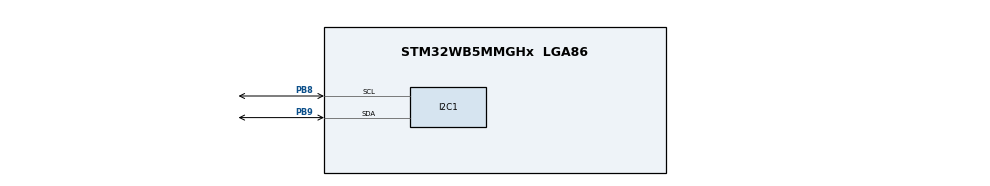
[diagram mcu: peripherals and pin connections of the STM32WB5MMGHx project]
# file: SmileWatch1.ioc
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I2C1.Timing=0x00100D14
Mcu.Family=STM32WB
Mcu.Name=STM32WB5MMGHx
Mcu.Package=LGA86
NVIC.PriorityGroup=NVIC_PRIORITYGROUP_4
PB8.Mode=I2C
PB8.Signal=I2C1_SCL
PB9.Mode=I2C
PB9.Signal=I2C1_SDA
ProjectManager.HeapSize=0x200
ProjectManager.StackSize=0x400
ProjectManager.TargetToolchain=STM32CubeIDE
RCC.APB3Freq_Value=16000000
RCC.HSE_VALUE=32000000
RCC.HSI48_VALUE=48000000
RCC.HSI_VALUE=16000000
RCC.VCOOutputFreq_Value=32000000
VP_MEMORYMAP_VS_MEMORYMAP.Mode=CurAppReg
board=custom

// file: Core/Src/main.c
/* USER CODE BEGIN Header */
/**
  ******************************************************************************
  * @file           : main.c
  * @brief          : Main program body — SmileWatch V2 (STM32WB55)
  ******************************************************************************
  * @attention
  *
  * Copyright (c) 2026 STMicroelectronics.
  * All rights reserved.
  *
  * This software is licensed under terms that can be found in the LICENSE file
  * in the root directory of this software component.
  * If no LICENSE file comes with this software, it is provided AS-IS.
  *
  ******************************************************************************
  */
/* USER CODE END Header */
#include "main.h"

/* USER CODE BEGIN Includes */
#include "smilewatch_ui.h"
/* USER CODE END Includes */

I2C_HandleTypeDef hi2c1;

void SystemClock_Config(void);
void PeriphCommonClock_Config(void);
static void MX_GPIO_Init(void);
static void MX_I2C1_Init(void);

int main(void)
{

  /* MCU Configuration--------------------------------------------------------*/

  /* Reset of all peripherals, Initializes the Flash interface and the Systick. */
  HAL_Init();

  /* Configure the system clock */
  SystemClock_Config();

  /* Configure the peripherals common clocks */
  PeriphCommonClock_Config();

  /* Initialize all configured peripherals */
  MX_GPIO_Init();
  MX_I2C1_Init();
  /* USER CODE BEGIN 2 */
  SmileWatch_Init(&hi2c1);
  /* USER CODE END 2 */

  /* Infinite loop */
  /* USER CODE BEGIN WHILE */
  while (1)
  {
    SmileWatch_LoopTask(HAL_GetTick());
    /* USER CODE END WHILE */

  }
}

void SystemClock_Config(void)
{
  RCC_OscInitTypeDef RCC_OscInitStruct = {0};
  RCC_ClkInitTypeDef RCC_ClkInitStruct = {0};

  /** Configure the main internal regulator output voltage
  */
  __HAL_PWR_VOLTAGESCALING_CONFIG(PWR_REGULATOR_VOLTAGE_SCALE1);

  /** Initializes the RCC Oscillators according to the specified parameters
  * in the RCC_OscInitTypeDef structure.
  */
  RCC_OscInitStruct.OscillatorType = RCC_OSCILLATORTYPE_HSI|RCC_OSCILLATORTYPE_MSI;
  RCC_OscInitStruct.HSIState = RCC_HSI_ON;
  RCC_OscInitStruct.MSIState = RCC_MSI_ON;
  RCC_OscInitStruct.HSICalibrationValue = RCC_HSICALIBRATION_DEFAULT;
  RCC_OscInitStruct.MSICalibrationValue = RCC_MSICALIBRATION_DEFAULT;
  RCC_OscInitStruct.MSIClockRange = RCC_MSIRANGE_6;
  RCC_OscInitStruct.PLL.PLLState = RCC_PLL_NONE;
  if (HAL_RCC_OscConfig(&RCC_OscInitStruct) != HAL_OK)
  {
    Error_Handler();
  }

  /** Configure the SYSCLKSource, HCLK, PCLK1 and PCLK2 clocks dividers
  */
  RCC_ClkInitStruct.ClockType = RCC_CLOCKTYPE_HCLK4|RCC_CLOCKTYPE_HCLK2
                              |RCC_CLOCKTYPE_HCLK|RCC_CLOCKTYPE_SYSCLK
                              |RCC_CLOCKTYPE_PCLK1|RCC_CLOCKTYPE_PCLK2;
  RCC_ClkInitStruct.SYSCLKSource = RCC_SYSCLKSOURCE_MSI;
  RCC_ClkInitStruct.AHBCLKDivider = RCC_SYSCLK_DIV1;
  RCC_ClkInitStruct.APB1CLKDivider = RCC_HCLK_DIV1;
  RCC_ClkInitStruct.APB2CLKDivider = RCC_HCLK_DIV1;
  RCC_ClkInitStruct.AHBCLK2Divider = RCC_SYSCLK_DIV1;
  RCC_ClkInitStruct.AHBCLK4Divider = RCC_SYSCLK_DIV1;

  if (HAL_RCC_ClockConfig(&RCC_ClkInitStruct, FLASH_LATENCY_0) != HAL_OK)
  {
    Error_Handler();
  }
}

void PeriphCommonClock_Config(void)
{
  RCC_PeriphCLKInitTypeDef PeriphClkInitStruct = {0};

  /** Initializes the peripherals clock
  */
  PeriphClkInitStruct.PeriphClockSelection = RCC_PERIPHCLK_SMPS;
  PeriphClkInitStruct.SmpsClockSelection = RCC_SMPSCLKSOURCE_HSI;
  PeriphClkInitStruct.SmpsDivSelection = RCC_SMPSCLKDIV_RANGE1;

  if (HAL_RCCEx_PeriphCLKConfig(&PeriphClkInitStruct) != HAL_OK)
  {
    Error_Handler();
  }
}

static void MX_I2C1_Init(void)
{

  hi2c1.Instance = I2C1;
  hi2c1.Init.Timing = 0x00100D14;
  hi2c1.Init.OwnAddress1 = 0;
  hi2c1.Init.AddressingMode = I2C_ADDRESSINGMODE_7BIT;
  hi2c1.Init.DualAddressMode = I2C_DUALADDRESS_DISABLE;
  hi2c1.Init.OwnAddress2 = 0;
  hi2c1.Init.OwnAddress2Masks = I2C_OA2_NOMASK;
  hi2c1.Init.GeneralCallMode = I2C_GENERALCALL_DISABLE;
  hi2c1.Init.NoStretchMode = I2C_NOSTRETCH_DISABLE;
  if (HAL_I2C_Init(&hi2c1) != HAL_OK)
  {
    Error_Handler();
  }

  /** Configure Analogue filter
  */
  if (HAL_I2CEx_ConfigAnalogFilter(&hi2c1, I2C_ANALOGFILTER_ENABLE) != HAL_OK)
  {
    Error_Handler();
  }

  /** Configure Digital filter
  */
  if (HAL_I2CEx_ConfigDigitalFilter(&hi2c1, 0) != HAL_OK)
  {
    Error_Handler();
  }

}

static void MX_GPIO_Init(void)
{

  /* GPIO Ports Clock Enable */
  __HAL_RCC_GPIOB_CLK_ENABLE();

  /* USER CODE BEGIN MX_GPIO_Init_2 */
  __HAL_RCC_GPIOA_CLK_ENABLE();
  __HAL_RCC_GPIOC_CLK_ENABLE();
  __HAL_RCC_GPIOD_CLK_ENABLE();

  GPIO_InitTypeDef GPIO_InitStruct = {0};

  /* Safe initial output states (Miyota LOW-LOW Lenz brake, OLED & Boost OFF) */
  HAL_GPIO_WritePin(GPIOA, MIYOTA_HP_Pin | DRV_EN_Pin | TCA_EN_Pin, GPIO_PIN_RESET);
  HAL_GPIO_WritePin(GPIOB, MIYOTA_HM_Pin | OLED_RES_Pin | HR_5V_EN_Pin, GPIO_PIN_RESET);
  HAL_GPIO_WritePin(GPIOD, OLED_PWR_EN_Pin, GPIO_PIN_RESET);

  /* Outputs on GPIOA: PA7 (Miyota H+), PA1 (DRV_EN), PA4 (TCA_EN) */
  GPIO_InitStruct.Pin   = MIYOTA_HP_Pin | DRV_EN_Pin | TCA_EN_Pin;
  GPIO_InitStruct.Mode  = GPIO_MODE_OUTPUT_PP;
  GPIO_InitStruct.Pull  = GPIO_NOPULL;
  GPIO_InitStruct.Speed = GPIO_SPEED_FREQ_LOW;
  HAL_GPIO_Init(GPIOA, &GPIO_InitStruct);

  /* Outputs on GPIOB: PB5 (Miyota H-), PB4 (OLED RES), PB0 (+5V_HR Boost EN) */
  GPIO_InitStruct.Pin   = MIYOTA_HM_Pin | OLED_RES_Pin | HR_5V_EN_Pin;
  GPIO_InitStruct.Mode  = GPIO_MODE_OUTPUT_PP;
  GPIO_InitStruct.Pull  = GPIO_NOPULL;
  GPIO_InitStruct.Speed = GPIO_SPEED_FREQ_LOW;
  HAL_GPIO_Init(GPIOB, &GPIO_InitStruct);

  /* Output on GPIOD: PD7 (OLED Power Switch GPIO_EC) */
  GPIO_InitStruct.Pin   = OLED_PWR_EN_Pin;
  GPIO_InitStruct.Mode  = GPIO_MODE_OUTPUT_PP;
  GPIO_InitStruct.Pull  = GPIO_NOPULL;
  GPIO_InitStruct.Speed = GPIO_SPEED_FREQ_LOW;
  HAL_GPIO_Init(GPIOD, &GPIO_InitStruct);

  /* Push-button inputs on GPIOC: PC5 (2h Top S2) & PC4 (4h Bottom S1) */
  GPIO_InitStruct.Pin   = BTN_TOP_2H_Pin | BTN_BOT_4H_Pin;
  GPIO_InitStruct.Mode  = GPIO_MODE_INPUT;
  GPIO_InitStruct.Pull  = GPIO_PULLUP;
  HAL_GPIO_Init(GPIOC, &GPIO_InitStruct);
  /* USER CODE END MX_GPIO_Init_2 */
}

void Error_Handler(void)
{
  __disable_irq();
  while (1)
  {
  }
}
